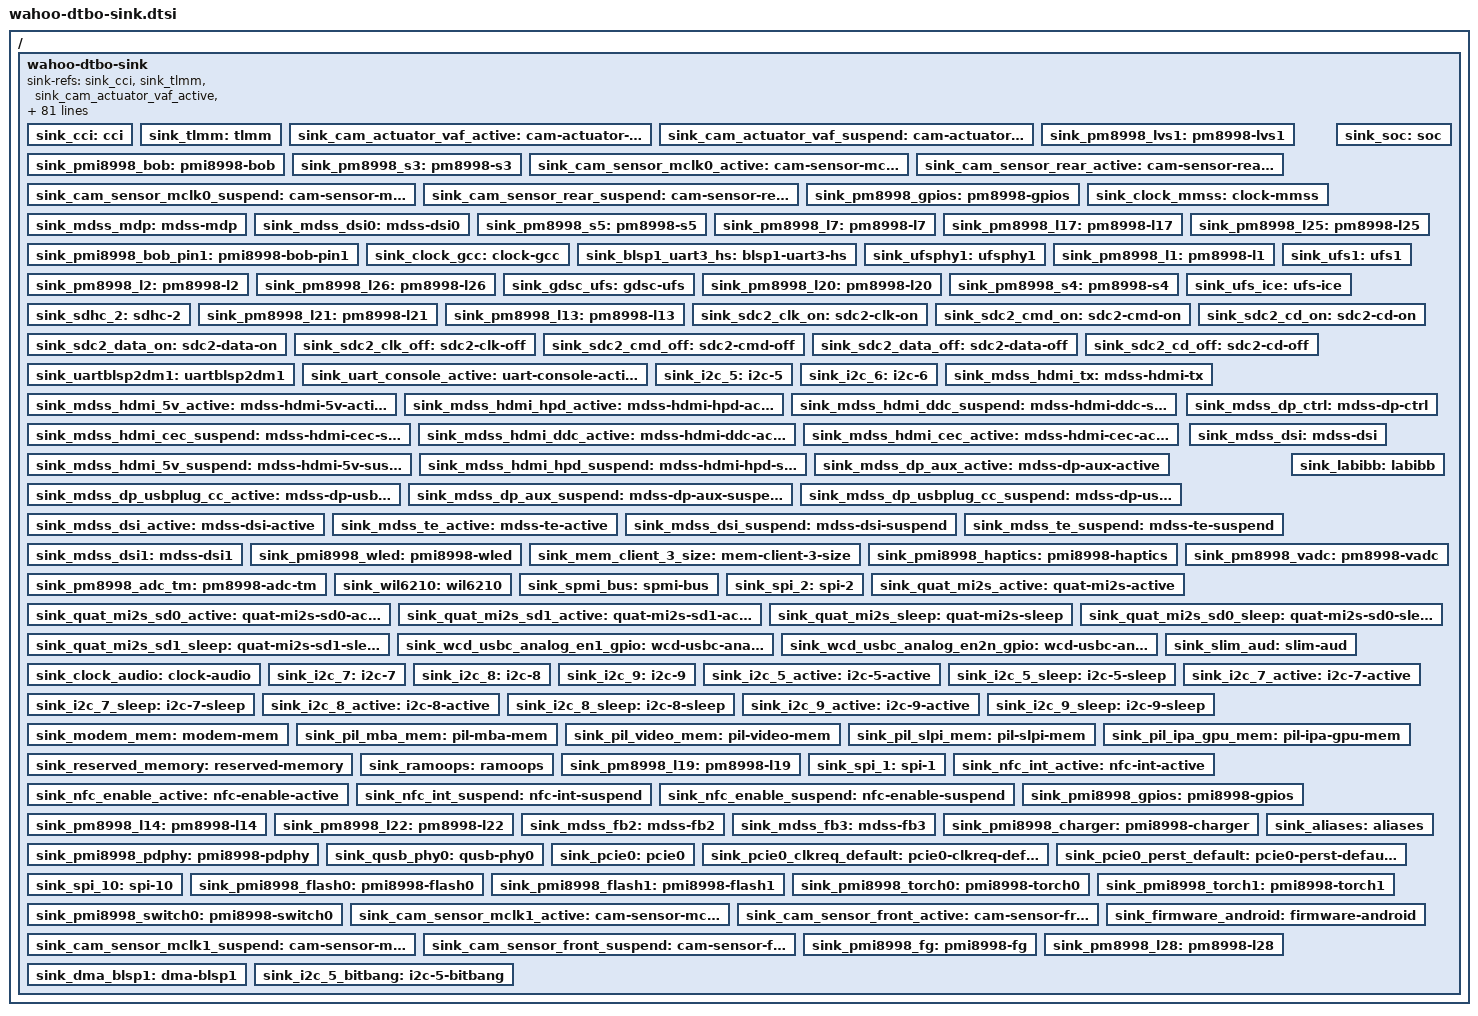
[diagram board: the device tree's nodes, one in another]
// SPDX-License-Identifier: GPL-2.0-only
/*
 * Sink for the stock walleye dtbo overlay (dtbo.img idx 3, id 444 rev 3).
 *
 * The bootloader always applies that overlay to the kernel's DTB and gets
 * stuck (later: "Load Error") when its label references can't be resolved;
 * a mainline DTB has no __symbols__. Here every label the overlay needs
 * (its __fixups__, 137 names) points at an empty node under /wahoo-dtbo-sink,
 * so the overlay applies there. The sink has no compatible, so Linux creates
 * no devices for anything below it. Hand-written __symbols__ (no dtc -@):
 * real mainline nodes are never exported, so the overlay can't touch them
 * even where label names overlap (tlmm, soc, spmi_bus, ...).
 * Label list: __fixups__ of the stock overlay (P8.3, docs/log.md).
 */

/ {
	wahoo-dtbo-sink {
		/* Referenced so dtc gives every dummy node a phandle: libfdt's
		 * fixup step needs one on each target (else FDT_ERR_NOTFOUND). */
		sink-refs = <&sink_cci &sink_tlmm &sink_cam_actuator_vaf_active &sink_cam_actuator_vaf_suspend &sink_pm8998_lvs1 &sink_pmi8998_bob &sink_pm8998_s3 &sink_cam_sensor_mclk0_active &sink_cam_sensor_rear_active &sink_cam_sensor_mclk0_suspend &sink_cam_sensor_rear_suspend &sink_pm8998_gpios &sink_clock_mmss &sink_mdss_mdp &sink_mdss_dsi0 &sink_soc &sink_pm8998_s5 &sink_pm8998_l7 &sink_pm8998_l17 &sink_pm8998_l25 &sink_pmi8998_bob_pin1 &sink_clock_gcc &sink_blsp1_uart3_hs &sink_ufsphy1 &sink_pm8998_l1 &sink_pm8998_l2 &sink_pm8998_l26 &sink_ufs1 &sink_gdsc_ufs &sink_pm8998_l20 &sink_pm8998_s4 &sink_ufs_ice &sink_sdhc_2 &sink_pm8998_l21 &sink_pm8998_l13 &sink_sdc2_clk_on &sink_sdc2_cmd_on &sink_sdc2_data_on &sink_sdc2_cd_on &sink_sdc2_clk_off &sink_sdc2_cmd_off &sink_sdc2_data_off &sink_sdc2_cd_off &sink_uartblsp2dm1 &sink_uart_console_active &sink_i2c_5 &sink_i2c_6 &sink_mdss_hdmi_tx &sink_mdss_hdmi_5v_active &sink_mdss_hdmi_hpd_active &sink_mdss_hdmi_ddc_suspend &sink_mdss_hdmi_cec_suspend &sink_mdss_hdmi_ddc_active &sink_mdss_hdmi_cec_active &sink_mdss_hdmi_5v_suspend &sink_mdss_hdmi_hpd_suspend &sink_mdss_dp_ctrl &sink_mdss_dp_aux_active &sink_mdss_dp_usbplug_cc_active &sink_mdss_dp_aux_suspend &sink_mdss_dp_usbplug_cc_suspend &sink_mdss_dsi &sink_mdss_dsi_active &sink_mdss_te_active &sink_mdss_dsi_suspend &sink_mdss_te_suspend &sink_mdss_dsi1 &sink_labibb &sink_pmi8998_wled &sink_mem_client_3_size &sink_pmi8998_haptics &sink_pm8998_vadc &sink_pm8998_adc_tm &sink_wil6210 &sink_spmi_bus &sink_spi_2 &sink_quat_mi2s_active &sink_quat_mi2s_sd0_active &sink_quat_mi2s_sd1_active &sink_quat_mi2s_sleep &sink_quat_mi2s_sd0_sleep &sink_quat_mi2s_sd1_sleep &sink_wcd_usbc_analog_en1_gpio &sink_wcd_usbc_analog_en2n_gpio &sink_slim_aud &sink_clock_audio &sink_i2c_7 &sink_i2c_8 &sink_i2c_9 &sink_i2c_5_active &sink_i2c_5_sleep &sink_i2c_7_active &sink_i2c_7_sleep &sink_i2c_8_active &sink_i2c_8_sleep &sink_i2c_9_active &sink_i2c_9_sleep &sink_modem_mem &sink_pil_mba_mem &sink_pil_video_mem &sink_pil_slpi_mem &sink_pil_ipa_gpu_mem &sink_reserved_memory &sink_ramoops &sink_pm8998_l19 &sink_spi_1 &sink_nfc_int_active &sink_nfc_enable_active &sink_nfc_int_suspend &sink_nfc_enable_suspend &sink_pmi8998_gpios &sink_pm8998_l14 &sink_pm8998_l22 &sink_mdss_fb2 &sink_mdss_fb3 &sink_pmi8998_charger &sink_pmi8998_pdphy &sink_qusb_phy0 &sink_aliases &sink_pcie0 &sink_pcie0_clkreq_default &sink_pcie0_perst_default &sink_spi_10 &sink_pmi8998_flash0 &sink_pmi8998_flash1 &sink_pmi8998_torch0 &sink_pmi8998_torch1 &sink_pmi8998_switch0 &sink_cam_sensor_mclk1_active &sink_cam_sensor_front_active &sink_cam_sensor_mclk1_suspend &sink_cam_sensor_front_suspend &sink_firmware_android &sink_pmi8998_fg &sink_pm8998_l28 &sink_dma_blsp1 &sink_i2c_5_bitbang>;

		sink_cci: cci {};
		sink_tlmm: tlmm {};
		sink_cam_actuator_vaf_active: cam-actuator-vaf-active {};
		sink_cam_actuator_vaf_suspend: cam-actuator-vaf-suspend {};
		sink_pm8998_lvs1: pm8998-lvs1 {};
		sink_pmi8998_bob: pmi8998-bob {};
		sink_pm8998_s3: pm8998-s3 {};
		sink_cam_sensor_mclk0_active: cam-sensor-mclk0-active {};
		sink_cam_sensor_rear_active: cam-sensor-rear-active {};
		sink_cam_sensor_mclk0_suspend: cam-sensor-mclk0-suspend {};
		sink_cam_sensor_rear_suspend: cam-sensor-rear-suspend {};
		sink_pm8998_gpios: pm8998-gpios {};
		sink_clock_mmss: clock-mmss {};
		sink_mdss_mdp: mdss-mdp {};
		sink_mdss_dsi0: mdss-dsi0 {};
		sink_soc: soc {};
		sink_pm8998_s5: pm8998-s5 {};
		sink_pm8998_l7: pm8998-l7 {};
		sink_pm8998_l17: pm8998-l17 {};
		sink_pm8998_l25: pm8998-l25 {};
		sink_pmi8998_bob_pin1: pmi8998-bob-pin1 {};
		sink_clock_gcc: clock-gcc {};
		sink_blsp1_uart3_hs: blsp1-uart3-hs {};
		sink_ufsphy1: ufsphy1 {};
		sink_pm8998_l1: pm8998-l1 {};
		sink_pm8998_l2: pm8998-l2 {};
		sink_pm8998_l26: pm8998-l26 {};
		sink_ufs1: ufs1 {};
		sink_gdsc_ufs: gdsc-ufs {};
		sink_pm8998_l20: pm8998-l20 {};
		sink_pm8998_s4: pm8998-s4 {};
		sink_ufs_ice: ufs-ice {};
		sink_sdhc_2: sdhc-2 {};
		sink_pm8998_l21: pm8998-l21 {};
		sink_pm8998_l13: pm8998-l13 {};
		sink_sdc2_clk_on: sdc2-clk-on {};
		sink_sdc2_cmd_on: sdc2-cmd-on {};
		sink_sdc2_data_on: sdc2-data-on {};
		sink_sdc2_cd_on: sdc2-cd-on {};
		sink_sdc2_clk_off: sdc2-clk-off {};
		sink_sdc2_cmd_off: sdc2-cmd-off {};
		sink_sdc2_data_off: sdc2-data-off {};
		sink_sdc2_cd_off: sdc2-cd-off {};
		sink_uartblsp2dm1: uartblsp2dm1 {};
		sink_uart_console_active: uart-console-active {};
		sink_i2c_5: i2c-5 {};
		sink_i2c_6: i2c-6 {};
		sink_mdss_hdmi_tx: mdss-hdmi-tx {};
		sink_mdss_hdmi_5v_active: mdss-hdmi-5v-active {};
		sink_mdss_hdmi_hpd_active: mdss-hdmi-hpd-active {};
		sink_mdss_hdmi_ddc_suspend: mdss-hdmi-ddc-suspend {};
		sink_mdss_hdmi_cec_suspend: mdss-hdmi-cec-suspend {};
		sink_mdss_hdmi_ddc_active: mdss-hdmi-ddc-active {};
		sink_mdss_hdmi_cec_active: mdss-hdmi-cec-active {};
		sink_mdss_hdmi_5v_suspend: mdss-hdmi-5v-suspend {};
		sink_mdss_hdmi_hpd_suspend: mdss-hdmi-hpd-suspend {};
		sink_mdss_dp_ctrl: mdss-dp-ctrl {};
		sink_mdss_dp_aux_active: mdss-dp-aux-active {};
		sink_mdss_dp_usbplug_cc_active: mdss-dp-usbplug-cc-active {};
		sink_mdss_dp_aux_suspend: mdss-dp-aux-suspend {};
		sink_mdss_dp_usbplug_cc_suspend: mdss-dp-usbplug-cc-suspend {};
		sink_mdss_dsi: mdss-dsi {};
		sink_mdss_dsi_active: mdss-dsi-active {};
		sink_mdss_te_active: mdss-te-active {};
		sink_mdss_dsi_suspend: mdss-dsi-suspend {};
		sink_mdss_te_suspend: mdss-te-suspend {};
		sink_mdss_dsi1: mdss-dsi1 {};
		sink_labibb: labibb {};
		sink_pmi8998_wled: pmi8998-wled {};
		sink_mem_client_3_size: mem-client-3-size {};
		sink_pmi8998_haptics: pmi8998-haptics {};
		sink_pm8998_vadc: pm8998-vadc {};
		sink_pm8998_adc_tm: pm8998-adc-tm {};
		sink_wil6210: wil6210 {};
		sink_spmi_bus: spmi-bus {};
		sink_spi_2: spi-2 {};
		sink_quat_mi2s_active: quat-mi2s-active {};
		sink_quat_mi2s_sd0_active: quat-mi2s-sd0-active {};
		sink_quat_mi2s_sd1_active: quat-mi2s-sd1-active {};
		sink_quat_mi2s_sleep: quat-mi2s-sleep {};
		sink_quat_mi2s_sd0_sleep: quat-mi2s-sd0-sleep {};
		sink_quat_mi2s_sd1_sleep: quat-mi2s-sd1-sleep {};
		sink_wcd_usbc_analog_en1_gpio: wcd-usbc-analog-en1-gpio {};
		sink_wcd_usbc_analog_en2n_gpio: wcd-usbc-analog-en2n-gpio {};
		sink_slim_aud: slim-aud {};
		sink_clock_audio: clock-audio {};
		sink_i2c_7: i2c-7 {};
		sink_i2c_8: i2c-8 {};
		sink_i2c_9: i2c-9 {};
		sink_i2c_5_active: i2c-5-active {};
		sink_i2c_5_sleep: i2c-5-sleep {};
		sink_i2c_7_active: i2c-7-active {};
		sink_i2c_7_sleep: i2c-7-sleep {};
		sink_i2c_8_active: i2c-8-active {};
		sink_i2c_8_sleep: i2c-8-sleep {};
		sink_i2c_9_active: i2c-9-active {};
		sink_i2c_9_sleep: i2c-9-sleep {};
		sink_modem_mem: modem-mem {};
		sink_pil_mba_mem: pil-mba-mem {};
		sink_pil_video_mem: pil-video-mem {};
		sink_pil_slpi_mem: pil-slpi-mem {};
		sink_pil_ipa_gpu_mem: pil-ipa-gpu-mem {};
		sink_reserved_memory: reserved-memory {};
		sink_ramoops: ramoops {};
		sink_pm8998_l19: pm8998-l19 {};
		sink_spi_1: spi-1 {};
		sink_nfc_int_active: nfc-int-active {};
		sink_nfc_enable_active: nfc-enable-active {};
		sink_nfc_int_suspend: nfc-int-suspend {};
		sink_nfc_enable_suspend: nfc-enable-suspend {};
		sink_pmi8998_gpios: pmi8998-gpios {};
		sink_pm8998_l14: pm8998-l14 {};
		sink_pm8998_l22: pm8998-l22 {};
		sink_mdss_fb2: mdss-fb2 {};
		sink_mdss_fb3: mdss-fb3 {};
		sink_pmi8998_charger: pmi8998-charger {};
		sink_pmi8998_pdphy: pmi8998-pdphy {};
		sink_qusb_phy0: qusb-phy0 {};
		sink_aliases: aliases {};
		sink_pcie0: pcie0 {};
		sink_pcie0_clkreq_default: pcie0-clkreq-default {};
		sink_pcie0_perst_default: pcie0-perst-default {};
		sink_spi_10: spi-10 {};
		sink_pmi8998_flash0: pmi8998-flash0 {};
		sink_pmi8998_flash1: pmi8998-flash1 {};
		sink_pmi8998_torch0: pmi8998-torch0 {};
		sink_pmi8998_torch1: pmi8998-torch1 {};
		sink_pmi8998_switch0: pmi8998-switch0 {};
		sink_cam_sensor_mclk1_active: cam-sensor-mclk1-active {};
		sink_cam_sensor_front_active: cam-sensor-front-active {};
		sink_cam_sensor_mclk1_suspend: cam-sensor-mclk1-suspend {};
		sink_cam_sensor_front_suspend: cam-sensor-front-suspend {};
		sink_firmware_android: firmware-android {};
		sink_pmi8998_fg: pmi8998-fg {};
		sink_pm8998_l28: pm8998-l28 {};
		sink_dma_blsp1: dma-blsp1 {};
		sink_i2c_5_bitbang: i2c-5-bitbang {};
	};

	__symbols__ {
		cci = "/wahoo-dtbo-sink/cci";
		tlmm = "/wahoo-dtbo-sink/tlmm";
		cam_actuator_vaf_active = "/wahoo-dtbo-sink/cam-actuator-vaf-active";
		cam_actuator_vaf_suspend = "/wahoo-dtbo-sink/cam-actuator-vaf-suspend";
		pm8998_lvs1 = "/wahoo-dtbo-sink/pm8998-lvs1";
		pmi8998_bob = "/wahoo-dtbo-sink/pmi8998-bob";
		pm8998_s3 = "/wahoo-dtbo-sink/pm8998-s3";
		cam_sensor_mclk0_active = "/wahoo-dtbo-sink/cam-sensor-mclk0-active";
		cam_sensor_rear_active = "/wahoo-dtbo-sink/cam-sensor-rear-active";
		cam_sensor_mclk0_suspend = "/wahoo-dtbo-sink/cam-sensor-mclk0-suspend";
		cam_sensor_rear_suspend = "/wahoo-dtbo-sink/cam-sensor-rear-suspend";
		pm8998_gpios = "/wahoo-dtbo-sink/pm8998-gpios";
		clock_mmss = "/wahoo-dtbo-sink/clock-mmss";
		mdss_mdp = "/wahoo-dtbo-sink/mdss-mdp";
		mdss_dsi0 = "/wahoo-dtbo-sink/mdss-dsi0";
		soc = "/wahoo-dtbo-sink/soc";
		pm8998_s5 = "/wahoo-dtbo-sink/pm8998-s5";
		pm8998_l7 = "/wahoo-dtbo-sink/pm8998-l7";
		pm8998_l17 = "/wahoo-dtbo-sink/pm8998-l17";
		pm8998_l25 = "/wahoo-dtbo-sink/pm8998-l25";
		pmi8998_bob_pin1 = "/wahoo-dtbo-sink/pmi8998-bob-pin1";
		clock_gcc = "/wahoo-dtbo-sink/clock-gcc";
		blsp1_uart3_hs = "/wahoo-dtbo-sink/blsp1-uart3-hs";
		ufsphy1 = "/wahoo-dtbo-sink/ufsphy1";
		pm8998_l1 = "/wahoo-dtbo-sink/pm8998-l1";
		pm8998_l2 = "/wahoo-dtbo-sink/pm8998-l2";
		pm8998_l26 = "/wahoo-dtbo-sink/pm8998-l26";
		ufs1 = "/wahoo-dtbo-sink/ufs1";
		gdsc_ufs = "/wahoo-dtbo-sink/gdsc-ufs";
		pm8998_l20 = "/wahoo-dtbo-sink/pm8998-l20";
		pm8998_s4 = "/wahoo-dtbo-sink/pm8998-s4";
		ufs_ice = "/wahoo-dtbo-sink/ufs-ice";
		sdhc_2 = "/wahoo-dtbo-sink/sdhc-2";
		pm8998_l21 = "/wahoo-dtbo-sink/pm8998-l21";
		pm8998_l13 = "/wahoo-dtbo-sink/pm8998-l13";
		sdc2_clk_on = "/wahoo-dtbo-sink/sdc2-clk-on";
		sdc2_cmd_on = "/wahoo-dtbo-sink/sdc2-cmd-on";
		sdc2_data_on = "/wahoo-dtbo-sink/sdc2-data-on";
		sdc2_cd_on = "/wahoo-dtbo-sink/sdc2-cd-on";
		sdc2_clk_off = "/wahoo-dtbo-sink/sdc2-clk-off";
		sdc2_cmd_off = "/wahoo-dtbo-sink/sdc2-cmd-off";
		sdc2_data_off = "/wahoo-dtbo-sink/sdc2-data-off";
		sdc2_cd_off = "/wahoo-dtbo-sink/sdc2-cd-off";
		uartblsp2dm1 = "/wahoo-dtbo-sink/uartblsp2dm1";
		uart_console_active = "/wahoo-dtbo-sink/uart-console-active";
		i2c_5 = "/wahoo-dtbo-sink/i2c-5";
		i2c_6 = "/wahoo-dtbo-sink/i2c-6";
		mdss_hdmi_tx = "/wahoo-dtbo-sink/mdss-hdmi-tx";
		mdss_hdmi_5v_active = "/wahoo-dtbo-sink/mdss-hdmi-5v-active";
		mdss_hdmi_hpd_active = "/wahoo-dtbo-sink/mdss-hdmi-hpd-active";
		mdss_hdmi_ddc_suspend = "/wahoo-dtbo-sink/mdss-hdmi-ddc-suspend";
		mdss_hdmi_cec_suspend = "/wahoo-dtbo-sink/mdss-hdmi-cec-suspend";
		mdss_hdmi_ddc_active = "/wahoo-dtbo-sink/mdss-hdmi-ddc-active";
		mdss_hdmi_cec_active = "/wahoo-dtbo-sink/mdss-hdmi-cec-active";
		mdss_hdmi_5v_suspend = "/wahoo-dtbo-sink/mdss-hdmi-5v-suspend";
		mdss_hdmi_hpd_suspend = "/wahoo-dtbo-sink/mdss-hdmi-hpd-suspend";
		mdss_dp_ctrl = "/wahoo-dtbo-sink/mdss-dp-ctrl";
		mdss_dp_aux_active = "/wahoo-dtbo-sink/mdss-dp-aux-active";
		mdss_dp_usbplug_cc_active = "/wahoo-dtbo-sink/mdss-dp-usbplug-cc-active";
		mdss_dp_aux_suspend = "/wahoo-dtbo-sink/mdss-dp-aux-suspend";
		mdss_dp_usbplug_cc_suspend = "/wahoo-dtbo-sink/mdss-dp-usbplug-cc-suspend";
		mdss_dsi = "/wahoo-dtbo-sink/mdss-dsi";
		mdss_dsi_active = "/wahoo-dtbo-sink/mdss-dsi-active";
		mdss_te_active = "/wahoo-dtbo-sink/mdss-te-active";
		mdss_dsi_suspend = "/wahoo-dtbo-sink/mdss-dsi-suspend";
		mdss_te_suspend = "/wahoo-dtbo-sink/mdss-te-suspend";
		mdss_dsi1 = "/wahoo-dtbo-sink/mdss-dsi1";
		labibb = "/wahoo-dtbo-sink/labibb";
		pmi8998_wled = "/wahoo-dtbo-sink/pmi8998-wled";
		mem_client_3_size = "/wahoo-dtbo-sink/mem-client-3-size";
		pmi8998_haptics = "/wahoo-dtbo-sink/pmi8998-haptics";
		pm8998_vadc = "/wahoo-dtbo-sink/pm8998-vadc";
		pm8998_adc_tm = "/wahoo-dtbo-sink/pm8998-adc-tm";
		wil6210 = "/wahoo-dtbo-sink/wil6210";
		spmi_bus = "/wahoo-dtbo-sink/spmi-bus";
		spi_2 = "/wahoo-dtbo-sink/spi-2";
		quat_mi2s_active = "/wahoo-dtbo-sink/quat-mi2s-active";
		quat_mi2s_sd0_active = "/wahoo-dtbo-sink/quat-mi2s-sd0-active";
		quat_mi2s_sd1_active = "/wahoo-dtbo-sink/quat-mi2s-sd1-active";
		quat_mi2s_sleep = "/wahoo-dtbo-sink/quat-mi2s-sleep";
		quat_mi2s_sd0_sleep = "/wahoo-dtbo-sink/quat-mi2s-sd0-sleep";
		quat_mi2s_sd1_sleep = "/wahoo-dtbo-sink/quat-mi2s-sd1-sleep";
		wcd_usbc_analog_en1_gpio = "/wahoo-dtbo-sink/wcd-usbc-analog-en1-gpio";
		wcd_usbc_analog_en2n_gpio = "/wahoo-dtbo-sink/wcd-usbc-analog-en2n-gpio";
		slim_aud = "/wahoo-dtbo-sink/slim-aud";
		clock_audio = "/wahoo-dtbo-sink/clock-audio";
		i2c_7 = "/wahoo-dtbo-sink/i2c-7";
		i2c_8 = "/wahoo-dtbo-sink/i2c-8";
		i2c_9 = "/wahoo-dtbo-sink/i2c-9";
		i2c_5_active = "/wahoo-dtbo-sink/i2c-5-active";
		i2c_5_sleep = "/wahoo-dtbo-sink/i2c-5-sleep";
		i2c_7_active = "/wahoo-dtbo-sink/i2c-7-active";
		i2c_7_sleep = "/wahoo-dtbo-sink/i2c-7-sleep";
		i2c_8_active = "/wahoo-dtbo-sink/i2c-8-active";
		i2c_8_sleep = "/wahoo-dtbo-sink/i2c-8-sleep";
		i2c_9_active = "/wahoo-dtbo-sink/i2c-9-active";
		i2c_9_sleep = "/wahoo-dtbo-sink/i2c-9-sleep";
		modem_mem = "/wahoo-dtbo-sink/modem-mem";
		pil_mba_mem = "/wahoo-dtbo-sink/pil-mba-mem";
		pil_video_mem = "/wahoo-dtbo-sink/pil-video-mem";
		pil_slpi_mem = "/wahoo-dtbo-sink/pil-slpi-mem";
		pil_ipa_gpu_mem = "/wahoo-dtbo-sink/pil-ipa-gpu-mem";
		reserved_memory = "/wahoo-dtbo-sink/reserved-memory";
		ramoops = "/wahoo-dtbo-sink/ramoops";
		pm8998_l19 = "/wahoo-dtbo-sink/pm8998-l19";
		spi_1 = "/wahoo-dtbo-sink/spi-1";
		nfc_int_active = "/wahoo-dtbo-sink/nfc-int-active";
		nfc_enable_active = "/wahoo-dtbo-sink/nfc-enable-active";
		nfc_int_suspend = "/wahoo-dtbo-sink/nfc-int-suspend";
		nfc_enable_suspend = "/wahoo-dtbo-sink/nfc-enable-suspend";
		pmi8998_gpios = "/wahoo-dtbo-sink/pmi8998-gpios";
		pm8998_l14 = "/wahoo-dtbo-sink/pm8998-l14";
		pm8998_l22 = "/wahoo-dtbo-sink/pm8998-l22";
		mdss_fb2 = "/wahoo-dtbo-sink/mdss-fb2";
		mdss_fb3 = "/wahoo-dtbo-sink/mdss-fb3";
		pmi8998_charger = "/wahoo-dtbo-sink/pmi8998-charger";
		pmi8998_pdphy = "/wahoo-dtbo-sink/pmi8998-pdphy";
		qusb_phy0 = "/wahoo-dtbo-sink/qusb-phy0";
		aliases = "/wahoo-dtbo-sink/aliases";
		pcie0 = "/wahoo-dtbo-sink/pcie0";
		pcie0_clkreq_default = "/wahoo-dtbo-sink/pcie0-clkreq-default";
		pcie0_perst_default = "/wahoo-dtbo-sink/pcie0-perst-default";
		spi_10 = "/wahoo-dtbo-sink/spi-10";
		pmi8998_flash0 = "/wahoo-dtbo-sink/pmi8998-flash0";
		pmi8998_flash1 = "/wahoo-dtbo-sink/pmi8998-flash1";
		pmi8998_torch0 = "/wahoo-dtbo-sink/pmi8998-torch0";
		pmi8998_torch1 = "/wahoo-dtbo-sink/pmi8998-torch1";
		pmi8998_switch0 = "/wahoo-dtbo-sink/pmi8998-switch0";
		cam_sensor_mclk1_active = "/wahoo-dtbo-sink/cam-sensor-mclk1-active";
		cam_sensor_front_active = "/wahoo-dtbo-sink/cam-sensor-front-active";
		cam_sensor_mclk1_suspend = "/wahoo-dtbo-sink/cam-sensor-mclk1-suspend";
		cam_sensor_front_suspend = "/wahoo-dtbo-sink/cam-sensor-front-suspend";
		firmware_android = "/wahoo-dtbo-sink/firmware-android";
		pmi8998_fg = "/wahoo-dtbo-sink/pmi8998-fg";
		pm8998_l28 = "/wahoo-dtbo-sink/pm8998-l28";
		dma_blsp1 = "/wahoo-dtbo-sink/dma-blsp1";
		i2c_5_bitbang = "/wahoo-dtbo-sink/i2c-5-bitbang";
	};
};
